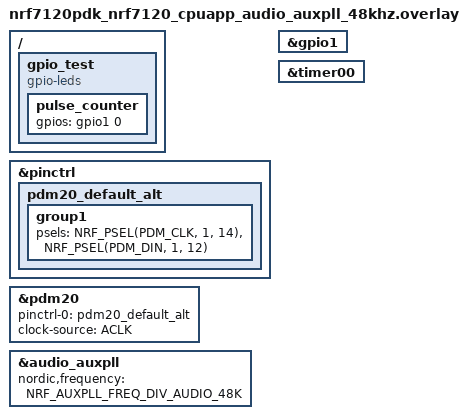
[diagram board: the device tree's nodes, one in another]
/*
 * Copyright (c) 2025 Nordic Semiconductor ASA
 *
 * SPDX-License-Identifier: LicenseRef-Nordic-5-Clause
 */
/* Loopback between P1.0 and P1.14 required */

/ {
	gpio_test {
		compatible = "gpio-leds";
		pulse_counter: pulse_counter {
			gpios = <&gpio1 0 GPIO_ACTIVE_HIGH>;
		};
	};
};

&pinctrl {
	pdm20_default_alt: pdm20_default_alt {
		group1 {
			psels = <NRF_PSEL(PDM_CLK, 1, 14)>,
				<NRF_PSEL(PDM_DIN, 1, 12)>;
		};
	};
};

pdm_dev: &pdm20 {
	status = "okay";
	pinctrl-0 = <&pdm20_default_alt>;
	pinctrl-names = "default";
	clock-source = "ACLK";
};

&audio_auxpll {
	nordic,frequency = <NRF_AUXPLL_FREQ_DIV_AUDIO_48K>;
	status = "okay";
};

&gpio1 {
	status = "okay";
};

&timer00 {
	status = "okay";
};
